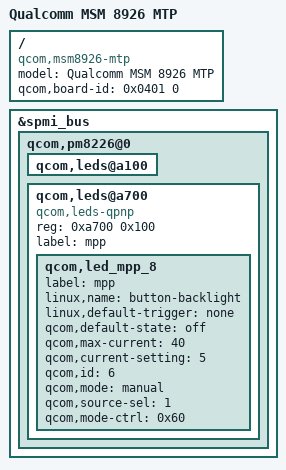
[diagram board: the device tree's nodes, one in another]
/* Copyright (c) 2013, The Linux Foundation. All rights reserved.
 *
 * This program is free software; you can redistribute it and/or modify
 * it under the terms of the GNU General Public License version 2 and
 * only version 2 as published by the Free Software Foundation.
 *
 * This program is distributed in the hope that it will be useful,
 * but WITHOUT ANY WARRANTY; without even the implied warranty of
 * MERCHANTABILITY or FITNESS FOR A PARTICULAR PURPOSE.  See the
 * GNU General Public License for more details.
 */


/dts-v1/;
/include/ "msm8926.dtsi"
/include/ "t3-msm8226-720p-mtp.dtsi"
/include/ "t3-msm8226-camera-sensor-mtp.dtsi"

/ {
	model = "Qualcomm MSM 8926 MTP";
	compatible = "qcom,msm8926-mtp", "qcom,msm8926", "qcom,mtp";
	qcom,board-id = <0x0401 0>;
};

&spmi_bus {
	qcom,pm8226@0 {
		qcom,leds@a100 {
			status = "okay";
		};
	};
};

&spmi_bus {
	qcom,pm8226@0 {
		qcom,leds@a700 {
			compatible = "qcom,leds-qpnp"; 
			reg = <0xa700 0x100>; 
			label = "mpp"; 
			status = "okay";
			qcom,led_mpp_8 {
				label = "mpp";
				linux,name = "button-backlight";
				linux,default-trigger = "none";
				qcom,default-state = "off";
				qcom,max-current = <40>;
				qcom,current-setting = <5>;
				qcom,id = <6>;
				qcom,mode = "manual";
				qcom,source-sel = <1>;
				qcom,mode-ctrl = <0x60>;
			};
		};
	};
};
